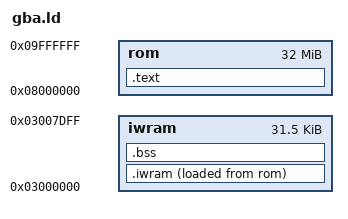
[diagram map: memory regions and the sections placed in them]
OUTPUT_FORMAT("elf32-littlearm")
OUTPUT_ARCH(arm)
ENTRY(_start)

MEMORY {
    rom   : ORIGIN = 0x08000000, LENGTH = 32M
    iwram : ORIGIN = 0x03000000, LENGTH = 0x7E00   /* the top holds the stacks and BIOS vars */
}

SECTIONS {
    .text : {
        KEEP(*(.crt0))
        *(.text .text.*)
        *(.rodata .rodata.*)
        . = ALIGN(4);
    } > rom

    .iwram : {
        __iwram_start = .;
        *(.iwram .iwram.*)
        *(.data .data.*)
        . = ALIGN(4);
        __iwram_end = .;
    } > iwram AT > rom
    __iwram_lma = LOADADDR(.iwram);

    .bss (NOLOAD) : {
        __bss_start = .;
        *(.bss .bss.*)
        *(COMMON)
        . = ALIGN(4);
        __bss_end = .;
    } > iwram

    /DISCARD/ : { *(.ARM.exidx*) *(.ARM.extab*) *(.comment) *(.note*) }
}
